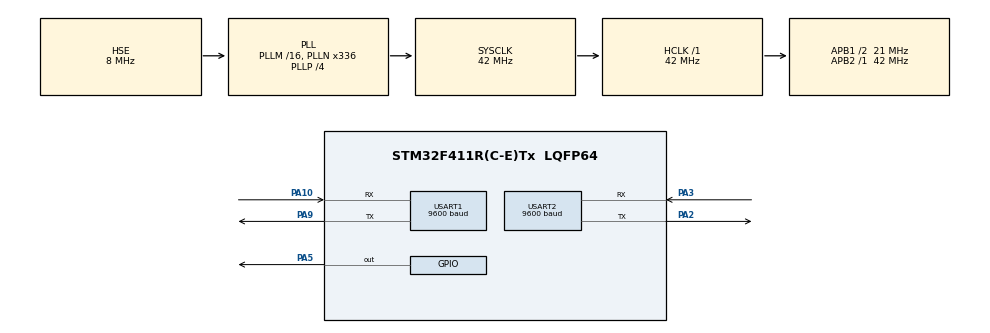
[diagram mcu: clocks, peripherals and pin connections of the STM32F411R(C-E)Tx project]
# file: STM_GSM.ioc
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Mcu.Family=STM32F4
Mcu.Name=STM32F411R(C-E)Tx
Mcu.Package=LQFP64
NVIC.PriorityGroup=NVIC_PRIORITYGROUP_0
NVIC.USART1_IRQn=true\:0\:0\:false\:false\:true\:true\:true\:true
NVIC.USART2_IRQn=true\:0\:0\:false\:false\:true\:true\:true\:true
PA10.Mode=Asynchronous
PA10.Signal=USART1_RX
PA2.Mode=Asynchronous
PA2.Signal=USART2_TX
PA3.Mode=Asynchronous
PA3.Signal=USART2_RX
PA5.Signal=GPIO_Output
PA9.Mode=Asynchronous
PA9.Signal=USART1_TX
PC14-OSC32_IN.Mode=LSE-External-Oscillator
PC14-OSC32_IN.Signal=RCC_OSC32_IN
PC15-OSC32_OUT.Mode=LSE-External-Oscillator
PC15-OSC32_OUT.Signal=RCC_OSC32_OUT
PH0\ -\ OSC_IN.Mode=HSE-External-Oscillator
PH0\ -\ OSC_IN.Signal=RCC_OSC_IN
PH1\ -\ OSC_OUT.Mode=HSE-External-Oscillator
PH1\ -\ OSC_OUT.Signal=RCC_OSC_OUT
ProjectManager.HeapSize=0x200
ProjectManager.StackSize=0x400
ProjectManager.TargetToolchain=STM32CubeIDE
RCC.48MHZClocksFreq_Value=42000000
RCC.AHBFreq_Value=42000000
RCC.APB1CLKDivider=RCC_HCLK_DIV2
RCC.APB1Freq_Value=21000000
RCC.APB1TimFreq_Value=42000000
RCC.APB2Freq_Value=42000000
RCC.APB2TimFreq_Value=42000000
RCC.CortexFreq_Value=42000000
RCC.FLatency-AdvancedSettings=FLASH_LATENCY_1
RCC.HCLKFreq_Value=42000000
RCC.HSE_VALUE=8000000
RCC.HSI_VALUE=16000000
RCC.PLLN=336
RCC.PLLP=RCC_PLLP_DIV4
RCC.PLLSourceVirtual=RCC_PLLSOURCE_HSE
RCC.SYSCLKFreq_VALUE=42000000
RCC.SYSCLKSource=RCC_SYSCLKSOURCE_PLLCLK
RCC.VCOOutputFreq_Value=168000000
USART1.BaudRate=9600
USART1.VirtualMode=VM_ASYNC
USART2.BaudRate=9600
USART2.VirtualMode=VM_ASYNC
board=NUCLEO-F411RE

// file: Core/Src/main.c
/* USER CODE BEGIN Header */
/**
  ******************************************************************************
  * @file           : main.c
  * @brief          : Main program body
  ******************************************************************************
  * @attention
  *
  * Copyright (c) 2023 STMicroelectronics.
  * All rights reserved.
  *
  * This software is licensed under terms that can be found in the LICENSE file
  * in the root directory of this software component.
  * If no LICENSE file comes with this software, it is provided AS-IS.
  *
  ******************************************************************************
  */
/* USER CODE END Header */
#include "main.h"
#include <string.h>
/* USER CODE BEGIN Includes */
#define RX_BUFFER_SIZE 128

uint8_t rxBuffer[RX_BUFFER_SIZE]; // Buffer to store UART1 received data
uint8_t responseBuffer[RX_BUFFER_SIZE]; // Buffer to store AT command response
/* USER CODE END Includes */

UART_HandleTypeDef huart1;
UART_HandleTypeDef huart2;

/* USER CODE BEGIN PV */
// Function to send data over UART
void UART1_SendString(const char *str) {
    HAL_UART_Transmit(&huart1, (uint8_t *)str, strlen(str), HAL_MAX_DELAY);
}

void HAL_UART_RxCpltCallback(UART_HandleTypeDef *huart) {
    if (huart == &huart1) {
        // Copy received data to the response buffer
        strcat((char *)responseBuffer, (const char *)rxBuffer);

        // Restart UART1 receive
        HAL_UART_Receive_IT(&huart1, rxBuffer, 1);
    }
}
/* USER CODE END PV */

void SystemClock_Config(void);
static void MX_GPIO_Init(void);
static void MX_USART1_UART_Init(void);
static void MX_USART2_UART_Init(void);

int main(void)
{

  /* MCU Configuration--------------------------------------------------------*/

  /* Reset of all peripherals, Initializes the Flash interface and the Systick. */
  HAL_Init();

  /* Configure the system clock */
  SystemClock_Config();

  /* Initialize all configured peripherals */
  MX_GPIO_Init();
  MX_USART1_UART_Init();
  MX_USART2_UART_Init();

  /* Infinite loop */
  // Start UART1 reception with interrupt
  HAL_UART_Receive_IT(&huart1, rxBuffer, 1);

   while (1) {
       // Clear the response buffer
       memset(responseBuffer, 0, RX_BUFFER_SIZE);

       char at_cmd[] = "AT\r\n";
       HAL_UART_Transmit(&huart1, (uint8_t *)at_cmd, strlen(at_cmd), HAL_MAX_DELAY);
       HAL_Delay(1000); // Delay to wait for the response
       // Send the response to UART2
       HAL_UART_Transmit(&huart2, responseBuffer, strlen((const char *)responseBuffer), HAL_MAX_DELAY);

       // Clear the response buffer again
       memset(responseBuffer, 0, RX_BUFFER_SIZE);

       char at_gsn[] = "AT+GSN\r\n";
       HAL_UART_Transmit(&huart1, (uint8_t *)at_gsn, strlen(at_gsn), HAL_MAX_DELAY);
       HAL_Delay(1000); // Delay to wait for the response
       // Send the response to UART2
       HAL_UART_Transmit(&huart2, responseBuffer, strlen((const char *)responseBuffer), HAL_MAX_DELAY);
   }
}
void SystemClock_Config(void)
{
  RCC_OscInitTypeDef RCC_OscInitStruct = {0};
  RCC_ClkInitTypeDef RCC_ClkInitStruct = {0};

  /** Configure the main internal regulator output voltage
  */
  __HAL_RCC_PWR_CLK_ENABLE();
  __HAL_PWR_VOLTAGESCALING_CONFIG(PWR_REGULATOR_VOLTAGE_SCALE1);

  /** Initializes the RCC Oscillators according to the specified parameters
  * in the RCC_OscInitTypeDef structure.
  */
  RCC_OscInitStruct.OscillatorType = RCC_OSCILLATORTYPE_HSE;
  RCC_OscInitStruct.HSEState = RCC_HSE_ON;
  RCC_OscInitStruct.PLL.PLLState = RCC_PLL_ON;
  RCC_OscInitStruct.PLL.PLLSource = RCC_PLLSOURCE_HSE;
  RCC_OscInitStruct.PLL.PLLM = 16;
  RCC_OscInitStruct.PLL.PLLN = 336;
  RCC_OscInitStruct.PLL.PLLP = RCC_PLLP_DIV4;
  RCC_OscInitStruct.PLL.PLLQ = 4;
  if (HAL_RCC_OscConfig(&RCC_OscInitStruct) != HAL_OK)
  {
    Error_Handler();
  }

  /** Initializes the CPU, AHB and APB buses clocks
  */
  RCC_ClkInitStruct.ClockType = RCC_CLOCKTYPE_HCLK|RCC_CLOCKTYPE_SYSCLK
                              |RCC_CLOCKTYPE_PCLK1|RCC_CLOCKTYPE_PCLK2;
  RCC_ClkInitStruct.SYSCLKSource = RCC_SYSCLKSOURCE_PLLCLK;
  RCC_ClkInitStruct.AHBCLKDivider = RCC_SYSCLK_DIV1;
  RCC_ClkInitStruct.APB1CLKDivider = RCC_HCLK_DIV2;
  RCC_ClkInitStruct.APB2CLKDivider = RCC_HCLK_DIV1;

  if (HAL_RCC_ClockConfig(&RCC_ClkInitStruct, FLASH_LATENCY_1) != HAL_OK)
  {
    Error_Handler();
  }
}

static void MX_USART1_UART_Init(void)
{

  huart1.Instance = USART1;
  huart1.Init.BaudRate = 9600;
  huart1.Init.WordLength = UART_WORDLENGTH_8B;
  huart1.Init.StopBits = UART_STOPBITS_1;
  huart1.Init.Parity = UART_PARITY_NONE;
  huart1.Init.Mode = UART_MODE_TX_RX;
  huart1.Init.HwFlowCtl = UART_HWCONTROL_NONE;
  huart1.Init.OverSampling = UART_OVERSAMPLING_16;
  if (HAL_UART_Init(&huart1) != HAL_OK)
  {
    Error_Handler();
  }

}

static void MX_USART2_UART_Init(void)
{

  huart2.Instance = USART2;
  huart2.Init.BaudRate = 9600;
  huart2.Init.WordLength = UART_WORDLENGTH_8B;
  huart2.Init.StopBits = UART_STOPBITS_1;
  huart2.Init.Parity = UART_PARITY_NONE;
  huart2.Init.Mode = UART_MODE_TX_RX;
  huart2.Init.HwFlowCtl = UART_HWCONTROL_NONE;
  huart2.Init.OverSampling = UART_OVERSAMPLING_16;
  if (HAL_UART_Init(&huart2) != HAL_OK)
  {
    Error_Handler();
  }

}

static void MX_GPIO_Init(void)
{
  GPIO_InitTypeDef GPIO_InitStruct = {0};

  /* GPIO Ports Clock Enable */
  __HAL_RCC_GPIOC_CLK_ENABLE();
  __HAL_RCC_GPIOH_CLK_ENABLE();
  __HAL_RCC_GPIOA_CLK_ENABLE();

  /*Configure GPIO pin Output Level */
  HAL_GPIO_WritePin(GPIOA, GPIO_PIN_5, GPIO_PIN_RESET);

  /*Configure GPIO pin : PA5 */
  GPIO_InitStruct.Pin = GPIO_PIN_5;
  GPIO_InitStruct.Mode = GPIO_MODE_OUTPUT_PP;
  GPIO_InitStruct.Pull = GPIO_NOPULL;
  GPIO_InitStruct.Speed = GPIO_SPEED_FREQ_LOW;
  HAL_GPIO_Init(GPIOA, &GPIO_InitStruct);

}

void Error_Handler(void)
{
  __disable_irq();
  while (1)
  {
  }
}
